# GD32F50x register map
File version: 1.0
CPU: CM33 r2p1, little endian, MPU, FPU, 4 interrupt priority bits
Registers are 32-bit, read-write, reset 0x0 unless marked. A register's access mark holds for its fields unless they carry their own. Offsets are from the block's base; [hi:lo] are bit positions; {n}, {i} and the like mark numbered series.

## CMP — Comparator
Base 0x40007800
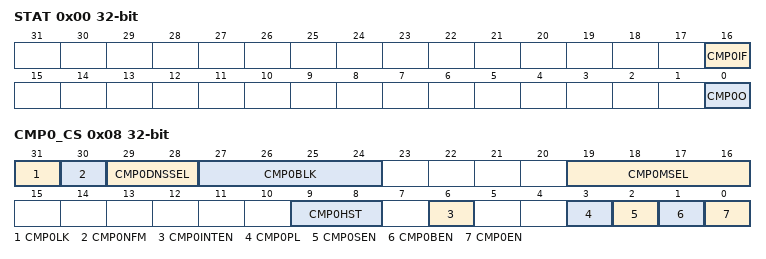
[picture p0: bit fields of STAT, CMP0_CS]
0x00 STAT ro — Status register
  [16] CMP0IF — CMP0 interrupt flag
  [0] CMP0O — CMP0 output state
0x04 IFC wo — Interrupt flag clear register
  [16] CMP0IC — CMP0 interrupt flag clear
0x08 CMP0_CS — CMP0 control/status register
  [31] CMP0LK — CMP0 lock
  [30] CMP0NFM — Noise filter mode
  [29:28] CMP0DNSSEL — CMP0 digital noise sampling selection.
  [27:24] CMP0BLK — CMP0 output blanking source
  [19:16] CMP0MSEL — CMP0_IM internal input selection
  [9:8] CMP0HST — CMP0 hysteresis
  [6] CMP0INTEN — CMP0 interrupt enable
  [3] CMP0PL — Polarity of CMP0 output
  [2] CMP0SEN — Voltage scaler enable bit
  [1] CMP0BEN — Scaler bridge enable bit
  [0] CMP0EN — CMP0 enable

## DAC — Digital-to-analog converter
Base 0x40007400
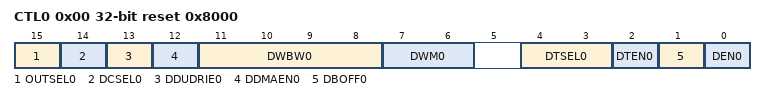
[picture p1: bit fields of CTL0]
0x00 CTL0 reset 0x8000 — DACx control register 0
  [15] OUTSEL0 — Select DACx_OUT0 connected to PA4 or PA5 pin
  [14] DCSEL0 — When DACx_OUT0 is connected to CMP, connection selection of DACx_OUT0 with GPIO:
  [13] DDUDRIE0 — DACx_OUT0 DMA underrun interrupt enable
  [12] DDMAEN0 — DACx_OUT0 DMA enable
  [11:8] DWBW0 — DACx_OUT0 noise wave bit width
  [7:6] DWM0 — DACx_OUT0 noise wave mode
  [4:3] DTSEL0 — DACx_OUT0 trigger selection
  [2] DTEN0 — DACx_OUT0 trigger enable
  [1] DBOFF0 — DACx_OUT0 output buffer turn off
  [0] DEN0 — DACx_OUT0 enable
0x04 SWT wo — DACx software trigger register
  [0] SWTR0 — DACx_OUT0 software trigger, cleared by hardware.
0x08 OUT0_R12DH — DACx_OUT0 12-bit right-aligned data holding register
  [11:0] OUT0_DH — DACx_OUT0 12-bit right-aligned data.
0x0C OUT0_L12DH — DACx_OUT0 12-bit left-aligned data holding register
  [15:4] OUT0_DH — DACx_OUT0 12-bit left-aligned data.
0x10 OUT0_R8DH — DACx_OUT0 8-bit right-aligned data holding register
  [7:0] OUT0_DH — DACx_OUT0 8-bit right-aligned data.
0x2C OUT0_DO ro — DACx_OUT0 data output register
  [11:0] OUT0_DO — DACx_OUT0 12-bit output data
0x34 STAT0 — DACx_OUT0 status register 0
  [13] DDUDR0 — DACx_OUT0 DMA underrun flag.

## DBG — Debug
Base 0xE0045000
0x00 ID ro — ID code register
  [31:0] ID_CODE — DBG ID code register
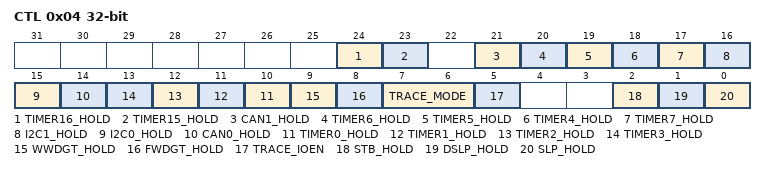
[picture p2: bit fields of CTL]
0x04 CTL — Control register
  [24] TIMER16_HOLD — TIMER 16 hold bit
  [23] TIMER15_HOLD — TIMER 15 hold bit
  [21] CAN1_HOLD — CAN1 hold bit
  [20] TIMER6_HOLD — TIMER6 hold bit
  [19] TIMER5_HOLD — TIMER5 hold bit
  [18] TIMER4_HOLD — TIMER4 hold bit
  [17] TIMER7_HOLD — TIMER7 hold bit
  [16] I2C1_HOLD — I2C1 hold bit
  [15] I2C0_HOLD — I2C0 hold bit
  [14] CAN0_HOLD — CAN0 hold bit
  [n+10] TIMER{n}_HOLD (n=0..3) — TIMER {n} hold bit
  [9] WWDGT_HOLD — WWDGT hold bit
  [8] FWDGT_HOLD — FWDGT hold bit
  [7:6] TRACE_MODE — Trace pin allocation mode
  [5] TRACE_IOEN — Trace pin allocation enable
  [2] STB_HOLD — Standby mode hold register
  [1] DSLP_HOLD — Deep-sleep mode hold register
  [0] SLP_HOLD — Sleep mode hold register

## DMA0 — DMA controller
Base 0x40020000
Same registers: DMA1 0x40020400
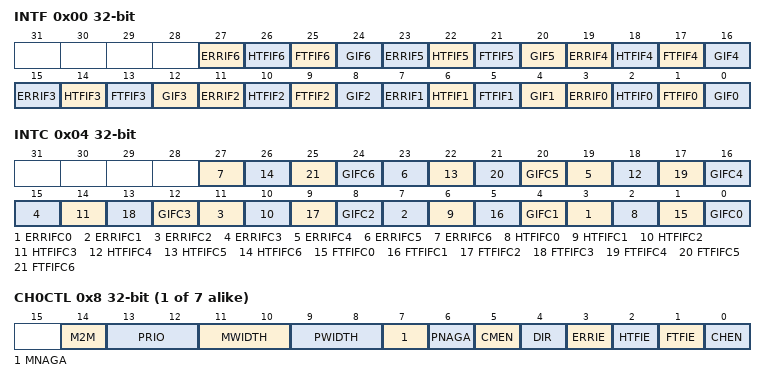
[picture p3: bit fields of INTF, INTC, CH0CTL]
0x00 INTF ro — Interrupt flag register
  [4n+3] ERRIF{n} (n=0..6) — Error flag of channel {n}
  [4n+2] HTFIF{n} (n=0..6) — Half transfer finish flag of channel {n}
  [4n+1] FTFIF{n} (n=0..6) — Full Transfer finish flag of channe {n}
  [4n] GIF{n} (n=0..6) — Global interrupt flag of channel {n}
0x04 INTC wo — Interrupt flag clear register
  [4n+3] ERRIFC{n} (n=0..6) — Clear bit for error flag of channel {n}
  [4n+2] HTFIFC{n} (n=0..6) — Clear bit for half transfer finish flag of channel {n}
  [4n+1] FTFIFC{n} (n=0..6) — Clear bit for full transfer finish flag of channel {n}
  [4n] GIFC{n} (n=0..6) — Clear global interrupt flag of channel {n}
{0x8+0x14*i} CH{i}CTL (i=0..6) — Channel {i} control register
  [14] M2M — Memory to Memory Mode
  [13:12] PRIO — Priority level
  [11:10] MWIDTH — Transfer data size of memory
  [9:8] PWIDTH — Transfer data size of peripheral
  [7] MNAGA — Next address generation algorithm of memory
  [6] PNAGA — Next address generation algorithm of peripheral
  [5] CMEN — Circular mode enable
  [4] DIR — Transfer direction
  [3] ERRIE — Enable bit for channel error interrupt
  [2] HTFIE — Enable bit for channel half transfer finish interrupt
  [1] FTFIE — Enable bit for channel full transfer finish interrupt
  [0] CHEN — Channel enable
{0xC+0x14*i} CH{i}CNT (i=0..6) — Channel {i} counter register
  [15:0] CNT — Transfer counter
{0x10+0x14*i} CH{i}PADDR (i=0..6) — Channel {i} peripheral base address register
  [31:0] PADDR — Peripheral base address
{0x14+0x14*i} CH{i}MADDR (i=0..6) — Channel {i} memory base address register
  [31:0] MADDR — Memory base address
